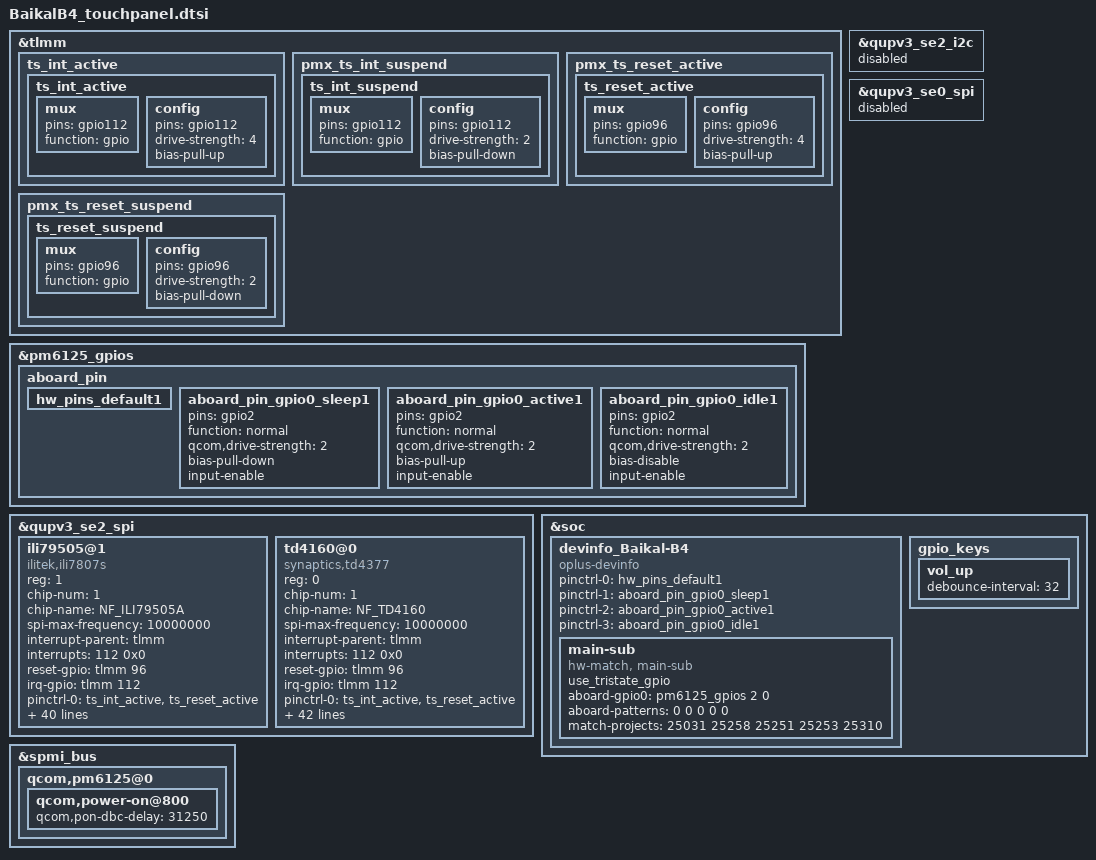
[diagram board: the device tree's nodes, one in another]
&tlmm {
	ts_int_active {
 		ts_int_active: ts_int_active {
 			mux {
				pins = "gpio112";
				function = "gpio";
 			};

 			config {
				pins = "gpio112";
 				drive-strength = <4>;
 				bias-pull-up;
 			};
 		};
 	};

 	pmx_ts_int_suspend {
 		ts_int_suspend: ts_int_suspend {
 			mux {
				pins = "gpio112";
 				function = "gpio";
 			};

 			config {
				pins = "gpio112";
 				drive-strength = <2>;
 				bias-pull-down;
 			};
 		};
 	};

 	pmx_ts_reset_active {
 		ts_reset_active: ts_reset_active {
 			mux {
				pins = "gpio96";
 				function = "gpio";
 			};

 			config {
				pins = "gpio96";
 				drive-strength = <4>;
 				bias-pull-up;
 			};
 		};
 	};

 	pmx_ts_reset_suspend {
 		ts_reset_suspend: ts_reset_suspend {
 			mux {
				pins = "gpio96";
 				function = "gpio";
 			};

 			config {
				pins = "gpio96";
 				drive-strength = <2>;
 				bias-pull-down;
 			};
 		};
 	};

};

&pm6125_gpios {
	aboard_pin {
		hw_pins_default1:hw_pins_default1 {
		};

		aboard_pin_gpio0_sleep1:aboard_pin_gpio0_sleep1 {
			pins = "gpio2";
			function = "normal";
			qcom,drive-strength = <2>;
			bias-pull-down;
			input-enable;
		};

		aboard_pin_gpio0_active1:aboard_pin_gpio0_active1 {
			pins = "gpio2";
			function = "normal";
			qcom,drive-strength = <2>;
			bias-pull-up;
			input-enable;
		};

		aboard_pin_gpio0_idle1:aboard_pin_gpio0_idle1 {
			pins = "gpio2";
			function = "normal";
			qcom,drive-strength = <2>;
			bias-disable;
			input-enable;
		};
	};
};

&qupv3_se2_spi {
	status = "ok";

	ili79505@1 {
		status = "ok";
		compatible = "ilitek,ili7807s";
		reg = <1>;
		chip-num = <1>;
		chip-name = "NF_ILI79505A";
		spi-max-frequency = <10000000>;

		/* Interrupt && Irq-gpio */
		interrupt-parent = <&tlmm>;
		interrupts = <112 0x0>;

		/* Other HW Resource */
		reset-gpio = <&tlmm 96 0x00>;
		irq-gpio = <&tlmm 112 0x2002>;

		pinctrl-names = "default", "suspend";
		pinctrl-0 = <&ts_int_active &ts_reset_active>;
		pinctrl-1 = <&ts_int_suspend &ts_reset_suspend>;

		touchpanel,irq_need_dev_resume_time = <500>;
		touchpanel,max-num-support = <10>;
		touchpanel,tx-rx-num = <18 32>;
		touchpanel,panel-coords = <2880 6280>;
		touchpanel,display-coords = <720 1570>;
		touchpanel,touchmajor-limit = <0 54>;
		touchpanel,single-optimized-time = <8>;
		touchpanel,smooth-level = <255 5 4 3 2 1>;
		touchpanel,sensitive-level = <255 1 2 3 4 5>;

		panel_type = <19>;
		firmware_name = "AC349tI0";
		platform_support_project = <25031 25248 25249 25258 25259 25251 25253 25310 25243>;
		platform_support_project_dir = <25031 25031 25031 25031 25031 25031 25031 25031 25031>;
		platform_support_project_commandline = "mdss_dsi_panel_AC349_P_4_A0030_video";

		incell_screen;
		fw_edge_limit_support;
		black_gesture_support;
		charger_pump_support;
		esd_handle_support;
		//spurious_fingerprint_support;
		//lcd_trigger_fp_check;
		black_gesture_test_support;
		noflash_support;
		smart_gesture_support;
		fw_update_app_support;
		game_switch_support;
		pressure_report_support;
		new_set_irq_wake_support;
		lcd_trigger_load_tp_fw_support;
		fw_update_in_probe_with_headfile;
		health_monitor_support;
		snr_read_support;
		glove_mode_v2_support;
		exception_upload_support;
		tp_data_record_support;
		waterproof_support;

		/*
		*Virtual Key Config:
		*1:touchpanel,button-type: <virtualkey_type  supportted_button-map>
		*virtualkey_type:
		*Type 1: using board_properties
		*Type 2: using same IC (button zone&& touch zone are seprate)
		*Type 3: using diffrent IC (button zone&& touch zone are seprate)
		*Type 4: No need of virtual key process
		*supportted_button-map:select|menu|home|back
		*
		*2:touchpanel,button-map
		*type (X1,Y1)(X2,Y2)(X3,Y3)(Width_X,Hight_Y)--Only when button-type is 0
		*/
		touchpanel,button-type = <4>;
		touchpanel.button-TRx = <0 0>;
	};

	td4160@0 {
		status = "ok";
		compatible = "synaptics,td4377";
		reg = <0>;
		chip-num = <1>;
		chip-name = "NF_TD4160";
		spi-max-frequency = <10000000>;

		/* Interrupt && Irq-gpio */
		interrupt-parent = <&tlmm>;
		interrupts = <112 0x0>;

		/* Other HW Resource */
		reset-gpio = <&tlmm 96 0x00>;
		irq-gpio = <&tlmm 112 0x2002>;

		pinctrl-names = "default", "suspend";
		pinctrl-0 = <&ts_int_active &ts_reset_active>;
		pinctrl-1 = <&ts_int_suspend &ts_reset_suspend>;

		touchpanel,irq_need_dev_resume_time = <500>;
		touchpanel,max-num-support = <10>;
		touchpanel,tx-rx-num = <18 32>;
		touchpanel,panel-coords = <2880 6280>;
		touchpanel,display-coords = <720 1570>;
		touchpanel,touchmajor-limit = <0 54>;
		touchpanel,single-optimized-time = <8>;
		touchpanel,smooth-level = <255 5 4 3 2 1>;
		touchpanel,sensitive-level = <255 1 2 3 4 5>;
		touchpanel,int-mode = <1>;

		panel_type = <15>;
		firmware_name = "0xAC349CT";
		platform_support_project = <25031 25248 25249 25258 25259 25251 25253 25310 25243>;
		platform_support_project_dir = <25031 25031 25031 25031 25031 25031 25031 25031 25031>;
		platform_support_project_commandline = "mdss_dsi_panel_AC349_P_D_A0018_video";

		incell_screen;
		fw_edge_limit_support;
		black_gesture_support;
		charger_pump_support;
		esd_handle_support;
		//spurious_fingerprint_support;
		//lcd_trigger_fp_check;
		black_gesture_test_support;
		noflash_support;
		smart_gesture_support;
		fw_update_app_support;
		pressure_report_support;
		new_set_irq_wake_support;
		lcd_trigger_load_tp_fw_support;
		fw_update_in_probe_with_headfile;
		health_monitor_support;
		snr_read_support;
		tp_data_record_support;
		glove_mode_v2_support;
		exception_upload_support;
		lpwg_fw_support;
		game_switch_support;
		waterproof_support;

		/*
		*Virtual Key Config:
		*1:touchpanel,button-type: <virtualkey_type  supportted_button-map>
		*virtualkey_type:
		*Type 1: using board_properties
		*Type 2: using same IC (button zone&& touch zone are seprate)
		*Type 3: using diffrent IC (button zone&& touch zone are seprate)
		*Type 4: No need of virtual key process
		*supportted_button-map:select|menu|home|back
		*
		*2:touchpanel,button-map
		*type (X1,Y1)(X2,Y2)(X3,Y3)(Width_X,Hight_Y)--Only when button-type is 0
		*/
		touchpanel,button-type = <4>;
		touchpanel.button-TRx = <0 0>;
	};
};

#include "BaikalB4-25031-tpfw.dtsi"

&qupv3_se2_i2c {
	status = "disabled";
};

&qupv3_se0_spi {
	status = "disabled";
 };

&soc {
	devinfo_Baikal-B4 {
		 compatible = "oplus-devinfo";

		 pinctrl-names = "default", "sleep", "active", "idle";
		 pinctrl-0 = <&hw_pins_default1>;
		 pinctrl-1 = <&aboard_pin_gpio0_sleep1>;
		 pinctrl-2 = <&aboard_pin_gpio0_active1>;
		 pinctrl-3 = <&aboard_pin_gpio0_idle1>;
		 main-sub {
				 use_tristate_gpio;
				 compatible = "hw-match, main-sub";
				 aboard-gpio0 = <&pm6125_gpios 2 0>;
				 aboard-patterns = <0 0 0 0 0>;    /*0[high-resistance] 1[pull-down] 2[pull-up]*/
				 /*main board*/
				 match-projects = <25031 25258 25251 25253 25310>;
		 };
	};
     gpio_keys {
		vol_up {
			debounce-interval = <32>;
		};
	};
};

&spmi_bus {
	qcom,pm6125@0 {
		qcom,power-on@800 {
		qcom,pon-dbc-delay = <31250>;
		};
	};
};
